# nrf5002 register map
Vendor: Nordic Semiconductor; Series: nRF50; File version: 1
CPU: CM0 r0p4, little endian, no MPU, no FPU, 2 interrupt priority bits, 32 interrupts
Registers are 32-bit, read-write, reset 0x0 unless marked. A register's access mark holds for its fields unless they carry their own. Offsets are from the block's base; [hi:lo] are bit positions; lines under a group give offsets from that group; {n}, {i} and the like mark numbered series; 'fields as' and 'values as' point back to an identical list.

## ECB — AES ECB Mode Encryption
Base 0x40009000
0x00 TASKS_STARTECB wo — Start ECB block encrypt
  [0] TASKS_STARTECB
    1=Trigger task
0x04 TASKS_STOPECB wo — Abort a possible executing ECB operation
  [0] TASKS_STOPECB
    1=Trigger task
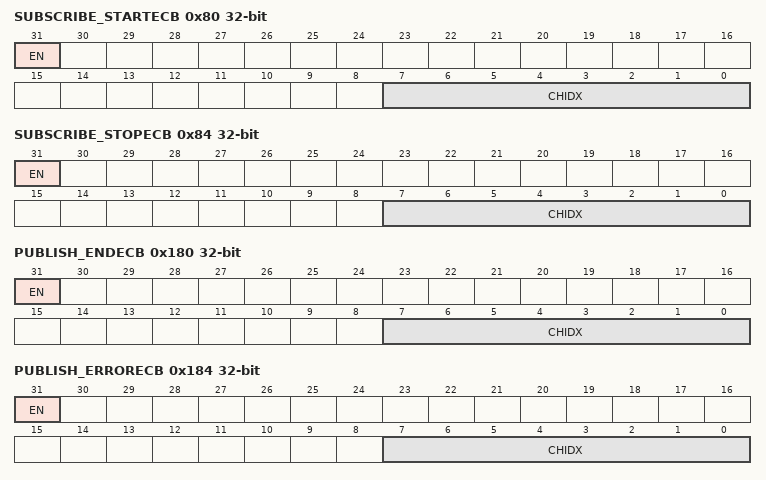
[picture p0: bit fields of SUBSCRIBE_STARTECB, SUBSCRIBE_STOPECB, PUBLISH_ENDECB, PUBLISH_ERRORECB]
0x80 SUBSCRIBE_STARTECB — Subscribe configuration for task STARTECB
  [31] EN
    0=Disabled (Disable subscription); 1=Enabled (Enable subscription)
  [7:0] CHIDX — DPPI channel that task STARTECB will subscribe to
0x84 SUBSCRIBE_STOPECB — Subscribe configuration for task STOPECB
  [31] EN
    values as SUBSCRIBE_STARTECB.EN
  [7:0] CHIDX — DPPI channel that task STOPECB will subscribe to
0x100 EVENTS_ENDECB — ECB block encrypt complete
  [0] EVENTS_ENDECB
    0=NotGenerated (Event not generated); 1=Generated (Event generated)
0x104 EVENTS_ERRORECB — ECB block encrypt aborted because of a STOPECB task or due to an error
  [0] EVENTS_ERRORECB
    values as EVENTS_ENDECB.EVENTS_ENDECB
0x180 PUBLISH_ENDECB — Publish configuration for event ENDECB
  [31] EN
    0=Disabled (Disable publishing); 1=Enabled (Enable publishing)
  [7:0] CHIDX — DPPI channel that event ENDECB will publish to
0x184 PUBLISH_ERRORECB — Publish configuration for event ERRORECB
  [31] EN
    values as PUBLISH_ENDECB.EN
  [7:0] CHIDX — DPPI channel that event ERRORECB will publish to
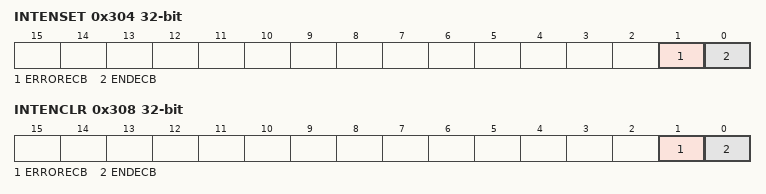
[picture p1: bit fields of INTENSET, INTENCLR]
0x304 INTENSET — Enable interrupt
  [1] ERRORECB — Write '1' to enable interrupt for event ERRORECB
    on read: 0=Disabled (Read: Disabled); 1=Enabled (Read: Enabled) | on write: 1=Set (Enable)
  [0] ENDECB — Write '1' to enable interrupt for event ENDECB
    values as ERRORECB
0x308 INTENCLR — Disable interrupt
  [1] ERRORECB — Write '1' to disable interrupt for event ERRORECB
    on read: 0=Disabled (Read: Disabled); 1=Enabled (Read: Enabled) | on write: 1=Clear (Disable)
  [0] ENDECB — Write '1' to disable interrupt for event ENDECB
    values as ERRORECB
0x504 ECBDATAPTR — ECB block encrypt memory pointers
  [31:0] ECBDATAPTR — Pointer to the ECB data structure (see Table 1 ECB data structure overview)
0xFFC POWER reset 0x1 — Peripheral power control
  [0] POWER — Peripheral power control. The peripheral and its registers will be reset to its initial state by switching the peripheral off and then back on again. All POWER registers in AAR, CCM and ECB must be disabled to see a reset of any of those functions.
    0=Disabled (Peripheral is powered off); 1=Enabled (Peripheral is powered on)

## DPPIC — Distributed programmable peripheral interconnect controller
Base 0x4000B000
{0x0+8i} TASKS_CHG[{i}] (i=0..5) group — Channel group tasks
  0x00 EN wo — Description cluster: Enable channel group n
    [0] EN — Enable channel group n
      1=Trigger task
  0x04 DIS wo — Description cluster: Disable channel group n
    [0] DIS — Disable channel group n
      1=Trigger task
{0x80+8i} SUBSCRIBE_CHG[{i}] (i=0..5) group — Subscribe configuration for tasks
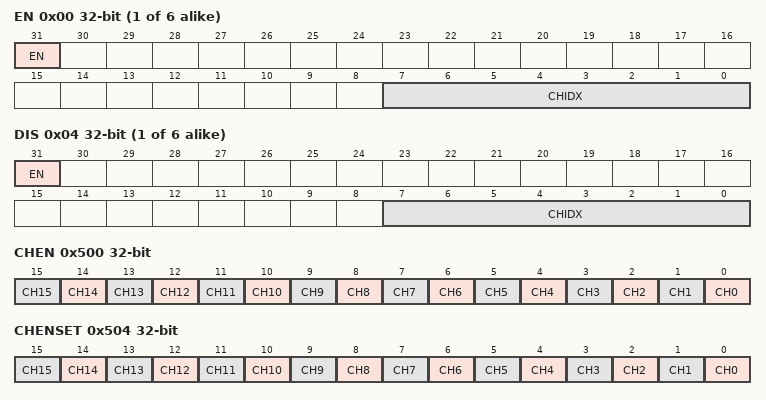
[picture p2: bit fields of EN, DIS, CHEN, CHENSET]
  0x00 EN — Description cluster: Subscribe configuration for task CHG[n].EN
    [31] EN
      0=Disabled (Disable subscription); 1=Enabled (Enable subscription)
    [7:0] CHIDX — DPPI channel that task CHG[n].EN will subscribe to
  0x04 DIS — Description cluster: Subscribe configuration for task CHG[n].DIS
    [31] EN
      values as SUBSCRIBE_CHG[0].EN.EN
    [7:0] CHIDX — DPPI channel that task CHG[n].DIS will subscribe to
0x500 CHEN — Channel enable register
  [all] fields
    0=Disabled (Disable channel); 1=Enabled (Enable channel)
  [n] CH{n} (n=0..15) — Enable or disable channel {n}
0x504 CHENSET write-1-sets — Channel enable set register
  [all] fields
    on read: 0=Disabled (Read: Channel disabled); 1=Enabled (Read: Channel enabled) | on write: 1=Set (Write: Enable channel)
  [n] CH{n} (n=0..15) — Channel {n} enable set register. Writing 0 has no effect.
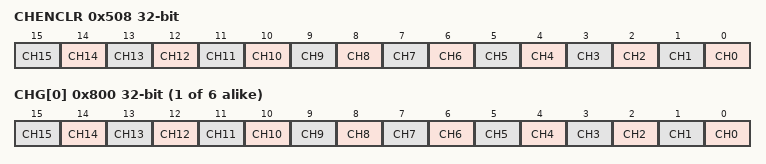
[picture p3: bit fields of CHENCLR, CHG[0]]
0x508 CHENCLR write-1-clears — Channel enable clear register
  [all] fields
    on read: 0=Disabled (Read: Channel disabled); 1=Enabled (Read: Channel enabled) | on write: 1=Clear (Write: Disable channel)
  [n] CH{n} (n=0..15) — Channel {n} enable clear register. Writing 0 has no effect.
{0x800+4i} CHG[{i}] (i=0..5) — Description collection: Channel group n Note: Writes to this register are ignored if either SUBSCRIBE_CHG[n].EN or SUBSCRIBE_CHG[n].DIS is enabled
  [all] fields
    0=Excluded; 1=Included
  [n] CH{n} (n=0..15) — Include or exclude channel {n}

## EGU0 — Event generator unit
Base 0x40017000
{0x0+4i} TASKS_TRIGGER[{i}] (i=0..15) wo — Description collection: Trigger n for triggering the corresponding TRIGGERED[n] event
  [0] TASKS_TRIGGER — Trigger n for triggering the corresponding TRIGGERED[n] event
    1=Trigger task
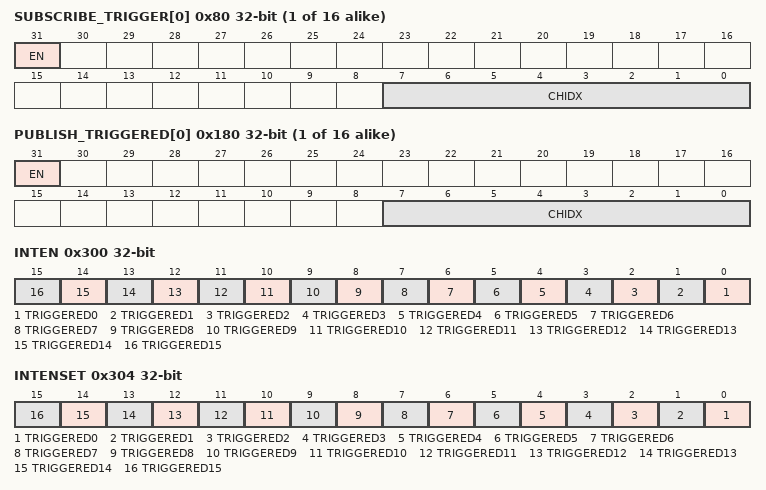
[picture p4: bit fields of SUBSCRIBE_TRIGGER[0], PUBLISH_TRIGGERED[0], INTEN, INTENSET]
{0x80+4i} SUBSCRIBE_TRIGGER[{i}] (i=0..15) — Description collection: Subscribe configuration for task TRIGGER[n]
  [31] EN
    0=Disabled (Disable subscription); 1=Enabled (Enable subscription)
  [7:0] CHIDX — DPPI channel that task TRIGGER[n] will subscribe to
{0x100+4i} EVENTS_TRIGGERED[{i}] (i=0..15) — Description collection: Event number n generated by triggering the corresponding TRIGGER[n] task
  [0] EVENTS_TRIGGERED — Event number n generated by triggering the corresponding TRIGGER[n] task
    0=NotGenerated (Event not generated); 1=Generated (Event generated)
{0x180+4i} PUBLISH_TRIGGERED[{i}] (i=0..15) — Description collection: Publish configuration for event TRIGGERED[n]
  [31] EN
    0=Disabled (Disable publishing); 1=Enabled (Enable publishing)
  [7:0] CHIDX — DPPI channel that event TRIGGERED[n] will publish to
0x300 INTEN — Enable or disable interrupt
  [all] fields
    0=Disabled; 1=Enabled
  [n] TRIGGERED{n} (n=0..15) — Enable or disable interrupt for event TRIGGERED[{n}]
0x304 INTENSET — Enable interrupt
  [all] fields
    on read: 0=Disabled (Read: Disabled); 1=Enabled (Read: Enabled) | on write: 1=Set (Enable)
  [n] TRIGGERED{n} (n=0..15) — Write '1' to enable interrupt for event TRIGGERED[{n}]
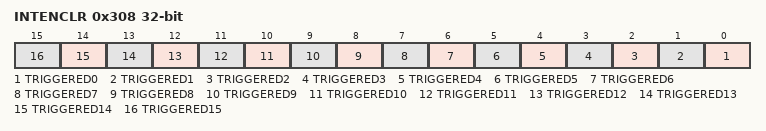
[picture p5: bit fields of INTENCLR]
0x308 INTENCLR — Disable interrupt
  [all] fields
    on read: 0=Disabled (Read: Disabled); 1=Enabled (Read: Enabled) | on write: 1=Clear (Disable)
  [n] TRIGGERED{n} (n=0..15) — Write '1' to disable interrupt for event TRIGGERED[{n}]

## SWI0 — Software interrupt 0
Base 0x40019000
Same registers: SWI1 0x4001A000, SWI2 0x4001B000
